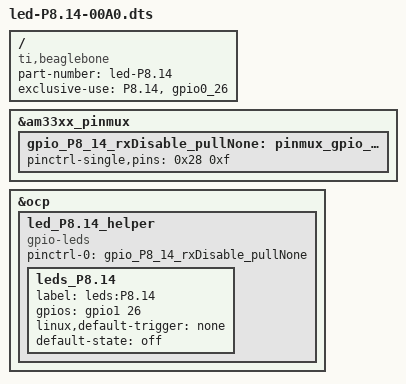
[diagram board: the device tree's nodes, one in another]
/*
* Easy gpio mux control of "P8.14" ("gpio0_26")
*/
/dts-v1/;
/plugin/;

/ {
	compatible = "ti,beaglebone", "ti,beaglebone-black";

	/* identification */
	part-number = "led-P8.14";
	/* version = "00A0"; */

	/* state the resources this cape uses */
	exclusive-use =
		/* the pin header uses */
		"P8.14",

		/* the hardware IP uses */
		"gpio0_26";
	
	
	/* rxDisable_pullNone state */
	fragment@0 {
		target = <&am33xx_pinmux>;
		__overlay__ {
			gpio_P8_14_rxDisable_pullNone: pinmux_gpio_P8.14_rxDisable_pullNone {
				pinctrl-single,pins = <
					0x28 0xf
				>;
			};
		};
	};

	fragment@1 {
		target = <&ocp>;
		__overlay__ {
			led_P8.14_helper {
				compatible = "gpio-leds";
				pinctrl-names = "default";
				pinctrl-0 = <&gpio_P8_14_rxDisable_pullNone>;
				
				leds_P8.14 {
					label = "leds:P8.14";
					gpios = <&gpio1 26 0>;
					linux,default-trigger = "none";
					default-state = "off";
				};
			};
			
		};
	};

};
